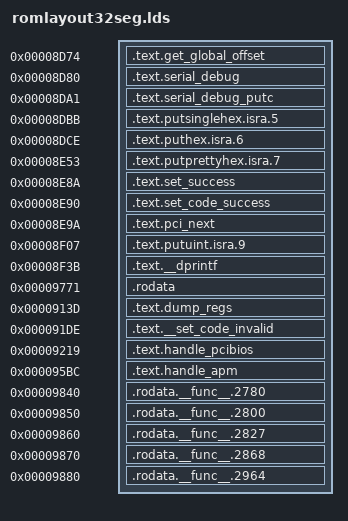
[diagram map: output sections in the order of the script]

/* DO NOT EDIT!  This is an autogenerated file.  See scripts/layoutrom.py. */
OUTPUT_FORMAT("elf32-i386")
OUTPUT_ARCH("i386")
SECTIONS
{
MaxPCIBus = 0x8bc8 ;
PirAddr = 0x8904 ;
entry_pcibios32 = 0xd009 ;
entry_apm16 = 0xcf96 ;
entry_apm32 = 0xcfd7 ;
acpi_pm1a_cnt = 0x8900 ;
.text.get_global_offset 0x8d74 : { *(.text.get_global_offset) }
.text.serial_debug 0x8d80 : { *(.text.serial_debug) }
.text.serial_debug_putc 0x8da1 : { *(.text.serial_debug_putc) }
.text.putsinglehex.isra.5 0x8dbb : { *(.text.putsinglehex.isra.5) }
.text.puthex.isra.6 0x8dce : { *(.text.puthex.isra.6) }
.text.putprettyhex.isra.7 0x8e53 : { *(.text.putprettyhex.isra.7) }
.text.set_success 0x8e8a : { *(.text.set_success) }
.text.set_code_success 0x8e90 : { *(.text.set_code_success) }
.text.pci_next 0x8e9a : { *(.text.pci_next) }
.text.putuint.isra.9 0x8f07 : { *(.text.putuint.isra.9) }
.text.__dprintf 0x8f3b : { *(.text.__dprintf) }
.rodata 0x9771 : { *(.rodata) }
.text.dump_regs 0x913d : { *(.text.dump_regs) }
.text.__set_code_invalid 0x91de : { *(.text.__set_code_invalid) }
.text.handle_pcibios 0x9219 : { *(.text.handle_pcibios) }
.text.handle_apm 0x95bc : { *(.text.handle_apm) }
.rodata.__func__.2780 0x9840 : { *(.rodata.__func__.2780) }
.rodata.__func__.2800 0x9850 : { *(.rodata.__func__.2800) }
.rodata.__func__.2827 0x9860 : { *(.rodata.__func__.2827) }
.rodata.__func__.2868 0x9870 : { *(.rodata.__func__.2868) }
.rodata.__func__.2964 0x9880 : { *(.rodata.__func__.2964) }


        /* Discard regular data sections to force a link error if
         * code attempts to access data not marked with VAR16 (or other
         * appropriate macro)
         */
        /DISCARD/ : {
                *(.text*) *(.data*) *(.bss*) *(.rodata*)
                *(COMMON) *(.discard*) *(.eh_frame) *(.note*)
                }
}
